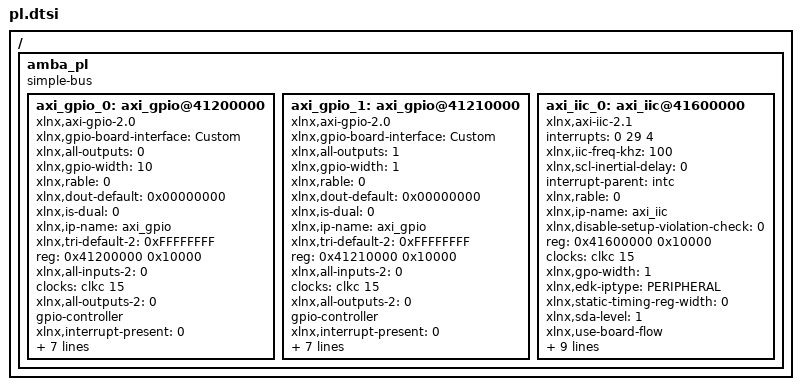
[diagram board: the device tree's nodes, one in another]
/ {
	amba_pl: amba_pl {
		ranges;
		compatible = "simple-bus";
		#address-cells = <1>;
		#size-cells = <1>;
		axi_gpio_0: axi_gpio@41200000 {
			xlnx,gpio-board-interface = "Custom";
			compatible = "xlnx,axi-gpio-2.0" , "xlnx,xps-gpio-1.00.a";
			xlnx,all-outputs = <0>;
			#gpio-cells = <2>;
			xlnx,gpio-width = <10>;
			xlnx,rable = <0>;
			xlnx,dout-default = <0x00000000>;
			xlnx,is-dual = <0>;
			xlnx,ip-name = "axi_gpio";
			xlnx,tri-default-2 = <0xFFFFFFFF>;
			reg = <0x41200000 0x10000>;
			xlnx,all-inputs-2 = <0>;
			clocks = <&clkc 15>;
			xlnx,all-outputs-2 = <0>;
			gpio-controller;
			xlnx,interrupt-present = <0>;
			xlnx,gpio2-board-interface = "Custom";
			xlnx,edk-iptype = "PERIPHERAL";
			xlnx,dout-default-2 = <0x00000000>;
			xlnx,gpio2-width = <32>;
			status = "okay";
			clock-names = "s_axi_aclk";
			xlnx,tri-default = <0xFFFFFFFF>;
			xlnx,name = "axi_gpio_0";
			xlnx,all-inputs = <1>;
		};
		axi_gpio_1: axi_gpio@41210000 {
			xlnx,gpio-board-interface = "Custom";
			compatible = "xlnx,axi-gpio-2.0" , "xlnx,xps-gpio-1.00.a";
			xlnx,all-outputs = <1>;
			#gpio-cells = <2>;
			xlnx,gpio-width = <1>;
			xlnx,rable = <0>;
			xlnx,dout-default = <0x00000000>;
			xlnx,is-dual = <0>;
			xlnx,ip-name = "axi_gpio";
			xlnx,tri-default-2 = <0xFFFFFFFF>;
			reg = <0x41210000 0x10000>;
			xlnx,all-inputs-2 = <0>;
			clocks = <&clkc 15>;
			xlnx,all-outputs-2 = <0>;
			gpio-controller;
			xlnx,interrupt-present = <0>;
			xlnx,gpio2-board-interface = "Custom";
			xlnx,edk-iptype = "PERIPHERAL";
			xlnx,dout-default-2 = <0x00000000>;
			xlnx,gpio2-width = <32>;
			status = "okay";
			clock-names = "s_axi_aclk";
			xlnx,tri-default = <0xFFFFFFFF>;
			xlnx,name = "axi_gpio_1";
			xlnx,all-inputs = <0>;
		};
		axi_iic_0: axi_iic@41600000 {
			interrupts = < 0 29 4 >;
			xlnx,iic-freq-khz = <100>;
			compatible = "xlnx,axi-iic-2.1" , "xlnx,xps-iic-2.00.a";
			xlnx,scl-inertial-delay = <0>;
			interrupt-parent = <&intc>;
			xlnx,rable = <0>;
			xlnx,ip-name = "axi_iic";
			xlnx,disable-setup-violation-check = <0>;
			reg = <0x41600000 0x10000>;
			clocks = <&clkc 15>;
			xlnx,gpo-width = <1>;
			xlnx,edk-iptype = "PERIPHERAL";
			xlnx,static-timing-reg-width = <0>;
			xlnx,sda-level = <1>;
			status = "okay";
			clock-names = "s_axi_aclk";
			xlnx,use-board-flow;
			xlnx,ten-bit-adr = <0>;
			xlnx,default-value = <0x00>;
			interrupt-names = "iic2intc_irpt";
			xlnx,timing-reg-width = <32>;
			xlnx,iic-board-interface = "respberry_i2c";
			xlnx,iic-freq = <100000>;
			xlnx,smbus-pmbus-host = <0>;
			xlnx,sda-inertial-delay = <0>;
			xlnx,name = "axi_iic_0";
			xlnx,axi-aclk-freq-mhz = <100>;
		};
	};
};
